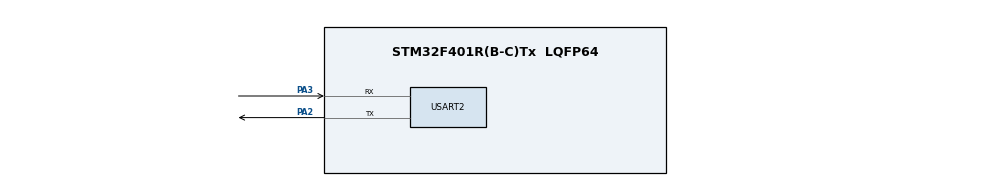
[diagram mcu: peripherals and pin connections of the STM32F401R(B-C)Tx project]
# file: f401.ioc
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Mcu.Family=STM32F4
Mcu.Name=STM32F401R(B-C)Tx
Mcu.Package=LQFP64
NVIC.PriorityGroup=NVIC_PRIORITYGROUP_4
NVIC.TIM1_UP_TIM10_IRQn=true\:0\:0\:false\:false\:true\:true\:true\:true
PA2.Mode=Asynchronous
PA2.Signal=USART2_TX
PA3.Mode=Asynchronous
PA3.Signal=USART2_RX
ProjectManager.HeapSize=0x200
ProjectManager.StackSize=0x400
ProjectManager.TargetToolchain=CMake
RCC.AHBFreq_Value=16000000
RCC.APB1Freq_Value=16000000
RCC.APB2Freq_Value=16000000
RCC.APB2TimFreq_Value=16000000
RCC.CortexFreq_Value=16000000
RCC.HSE_VALUE=25000000
RCC.HSI_VALUE=16000000
RCC.LSE_VALUE=32768
RCC.SYSCLKFreq_VALUE=16000000
RCC.VCOOutputFreq_Value=192000000
TIM1.Period=124
TIM1.Prescaler=7
TIM1.TIM_MasterOutputTrigger=TIM_TRGO_UPDATE
USART2.VirtualMode=VM_ASYNC
VP_TIM1_VS_ClockSourceINT.Mode=Internal
board=custom

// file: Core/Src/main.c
/* USER CODE BEGIN Header */
/**
  ******************************************************************************
  * @file           : main.c
  * @brief          : Main program body
  ******************************************************************************
  * @attention
  *
  * Copyright (c) 2026 STMicroelectronics.
  * All rights reserved.
  *
  * This software is licensed under terms that can be found in the LICENSE file
  * in the root directory of this software component.
  * If no LICENSE file comes with this software, it is provided AS-IS.
  *
  ******************************************************************************
  */
/* USER CODE END Header */
#include "main.h"

/* USER CODE BEGIN Includes */
#include "api.h"

/* USER CODE END Includes */

/* USER CODE BEGIN PD */
#define STR(s) #s
#define XSTR(s) STR(s)
/* USER CODE END PD */

void SystemClock_Config(void);
static void MX_GPIO_Init(void);
static void MX_TIM1_Init(void);
static void MX_USART2_UART_Init(void);

/* USER CODE BEGIN 0 */

#define BUFFER_SIZE 512

Oscillator osc;

sound_sample_t g_buffer[BUFFER_SIZE] = {0};
unsigned int g_buffer_samples_written = 0;

void UART_Print(const char *string)
{
  for (int i = 0; string[i] != '\0'; i++)
  {
      while(!LL_USART_IsActiveFlag_TXE(USART2));
      LL_USART_TransmitData8(USART2, string[i]);
  }
}

void BufferFullCallback(void)
{
    UART_Print("Buffer is full!\r\n");
}

void TIM1_UP_Callback(void)
{
    static unsigned int sample_i = 0;
    g_buffer[sample_i] = GetSample(&osc);
    sample_i++;
    if (sample_i == BUFFER_SIZE)
    {
	sample_i = 0;
	g_buffer_samples_written += BUFFER_SIZE;
	BufferFullCallback();
    }
}

/* USER CODE END 0 */

int main(void)
{

  /* MCU Configuration--------------------------------------------------------*/

  /* Reset of all peripherals, Initializes the Flash interface and the Systick. */
  LL_APB2_GRP1_EnableClock(LL_APB2_GRP1_PERIPH_SYSCFG);
  LL_APB1_GRP1_EnableClock(LL_APB1_GRP1_PERIPH_PWR);

  /* System interrupt init*/
  NVIC_SetPriorityGrouping(NVIC_PRIORITYGROUP_4);

  /* SysTick_IRQn interrupt configuration */
  NVIC_SetPriority(SysTick_IRQn, NVIC_EncodePriority(NVIC_GetPriorityGrouping(),15, 0));

  /* Configure the system clock */
  SystemClock_Config();

  /* Initialize all configured peripherals */
  MX_GPIO_Init();
  MX_TIM1_Init();
  MX_USART2_UART_Init();
  /* USER CODE BEGIN 2 */
  UART_Print("Rate: " XSTR(SAMPLING_RATE) "\r\n");
  LL_mDelay(200);
  InitOsc(osc, 220.0f);
  LL_TIM_EnableIT_UPDATE(TIM1);
  LL_TIM_EnableCounter(TIM1);

  /* USER CODE END 2 */

  /* Infinite loop */
  while (1)
  {

  }
}

void SystemClock_Config(void)
{
  LL_FLASH_SetLatency(LL_FLASH_LATENCY_0);
  while(LL_FLASH_GetLatency()!= LL_FLASH_LATENCY_0)
  {
  }
  LL_PWR_SetRegulVoltageScaling(LL_PWR_REGU_VOLTAGE_SCALE2);
  LL_RCC_HSI_SetCalibTrimming(16);
  LL_RCC_HSI_Enable();

   /* Wait till HSI is ready */
  while(LL_RCC_HSI_IsReady() != 1)
  {

  }
  LL_RCC_SetAHBPrescaler(LL_RCC_SYSCLK_DIV_1);
  LL_RCC_SetAPB1Prescaler(LL_RCC_APB1_DIV_1);
  LL_RCC_SetAPB2Prescaler(LL_RCC_APB2_DIV_1);
  LL_RCC_SetSysClkSource(LL_RCC_SYS_CLKSOURCE_HSI);

   /* Wait till System clock is ready */
  while(LL_RCC_GetSysClkSource() != LL_RCC_SYS_CLKSOURCE_STATUS_HSI)
  {

  }
  LL_Init1msTick(16000000);
  LL_SetSystemCoreClock(16000000);
  LL_RCC_SetTIMPrescaler(LL_RCC_TIM_PRESCALER_TWICE);
}

static void MX_TIM1_Init(void)
{

  LL_TIM_InitTypeDef TIM_InitStruct = {0};

  /* Peripheral clock enable */
  LL_APB2_GRP1_EnableClock(LL_APB2_GRP1_PERIPH_TIM1);

  /* TIM1 interrupt Init */
  NVIC_SetPriority(TIM1_UP_TIM10_IRQn, NVIC_EncodePriority(NVIC_GetPriorityGrouping(),0, 0));
  NVIC_EnableIRQ(TIM1_UP_TIM10_IRQn);

  TIM_InitStruct.Prescaler = 7;
  TIM_InitStruct.CounterMode = LL_TIM_COUNTERMODE_UP;
  TIM_InitStruct.Autoreload = 124;
  TIM_InitStruct.ClockDivision = LL_TIM_CLOCKDIVISION_DIV1;
  TIM_InitStruct.RepetitionCounter = 0;
  LL_TIM_Init(TIM1, &TIM_InitStruct);
  LL_TIM_DisableARRPreload(TIM1);
  LL_TIM_SetClockSource(TIM1, LL_TIM_CLOCKSOURCE_INTERNAL);
  LL_TIM_SetTriggerOutput(TIM1, LL_TIM_TRGO_UPDATE);
  LL_TIM_DisableMasterSlaveMode(TIM1);

}

static void MX_USART2_UART_Init(void)
{

  LL_USART_InitTypeDef USART_InitStruct = {0};

  LL_GPIO_InitTypeDef GPIO_InitStruct = {0};

  /* Peripheral clock enable */
  LL_APB1_GRP1_EnableClock(LL_APB1_GRP1_PERIPH_USART2);

  LL_AHB1_GRP1_EnableClock(LL_AHB1_GRP1_PERIPH_GPIOA);
  /**USART2 GPIO Configuration
  PA2   ------> USART2_TX
  PA3   ------> USART2_RX
  */
  GPIO_InitStruct.Pin = LL_GPIO_PIN_2|LL_GPIO_PIN_3;
  GPIO_InitStruct.Mode = LL_GPIO_MODE_ALTERNATE;
  GPIO_InitStruct.Speed = LL_GPIO_SPEED_FREQ_VERY_HIGH;
  GPIO_InitStruct.OutputType = LL_GPIO_OUTPUT_PUSHPULL;
  GPIO_InitStruct.Pull = LL_GPIO_PULL_NO;
  GPIO_InitStruct.Alternate = LL_GPIO_AF_7;
  LL_GPIO_Init(GPIOA, &GPIO_InitStruct);

  USART_InitStruct.BaudRate = 115200;
  USART_InitStruct.DataWidth = LL_USART_DATAWIDTH_8B;
  USART_InitStruct.StopBits = LL_USART_STOPBITS_1;
  USART_InitStruct.Parity = LL_USART_PARITY_NONE;
  USART_InitStruct.TransferDirection = LL_USART_DIRECTION_TX_RX;
  USART_InitStruct.HardwareFlowControl = LL_USART_HWCONTROL_NONE;
  USART_InitStruct.OverSampling = LL_USART_OVERSAMPLING_16;
  LL_USART_Init(USART2, &USART_InitStruct);
  LL_USART_ConfigAsyncMode(USART2);
  LL_USART_Enable(USART2);

}

static void MX_GPIO_Init(void)
{

  /* GPIO Ports Clock Enable */
  LL_AHB1_GRP1_EnableClock(LL_AHB1_GRP1_PERIPH_GPIOA);

}

void Error_Handler(void)
{
  __disable_irq();
  while (1)
  {
  }
}
